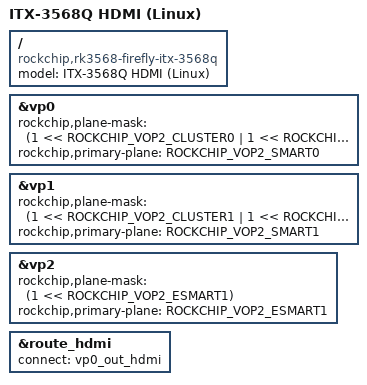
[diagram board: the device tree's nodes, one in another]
// SPDX-License-Identifier: (GPL-2.0+ OR MIT)
/*
 * Copyright (c) 2020 Rockchip Electronics Co., Ltd.
 *
 */

/dts-v1/;

#include "rk3568-firefly-itx-3568q.dtsi"

/*
* Screen.
*/
#include "rk3568-firefly-itx-3568q-EDPtoVGA_LT8711V.dtsi"
#include "rk3568-firefly-itx-3568q-RGBtoVGA_ADV7123.dtsi"


/*
 * Camera.Select one of the three
 * using single camera xc7160 ----> rk3568-firefly-itx-3568q-cam-8ms1m.dtsi
 * using dual camera gc2053/gc2093   ----> rk3568-firefly-itx-3568q-cam-2ms2m.dtsi
 * using hdmi-in module rk628d   ----> rk3568-firefly-itx-3568q-hdmi-mipi-rk628.dtsi
 */
//#include "rk3568-firefly-itx-3568q-cam-8ms1m.dtsi"
#include "rk3568-firefly-itx-3568q-cam-2ms2m.dtsi"
//#include "rk3568-firefly-itx-3568q-hdmi-mipi-rk628.dtsi"


/ {
    model = "ITX-3568Q HDMI (Linux)";
    compatible = "rockchip,rk3568-firefly-itx-3568q", "rockchip,rk3568";
};

&vp0 {
	rockchip,plane-mask = <(1 << ROCKCHIP_VOP2_CLUSTER0 | 1 << ROCKCHIP_VOP2_ESMART0 | 1 << ROCKCHIP_VOP2_SMART0)>;
	rockchip,primary-plane = <ROCKCHIP_VOP2_SMART0>;
};

&vp1 {
	rockchip,plane-mask = <(1 << ROCKCHIP_VOP2_CLUSTER1 | 1 << ROCKCHIP_VOP2_SMART1)>;
	rockchip,primary-plane = <ROCKCHIP_VOP2_SMART1>;
};

&vp2 {
	rockchip,plane-mask = <(1 << ROCKCHIP_VOP2_ESMART1)>;
	rockchip,primary-plane = <ROCKCHIP_VOP2_ESMART1>;
};

&route_hdmi {
    status = "okay";
    connect = <&vp0_out_hdmi>;
};
